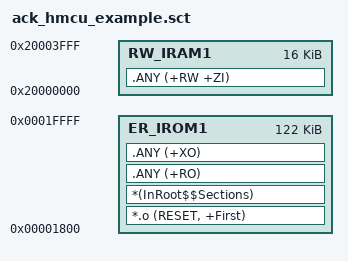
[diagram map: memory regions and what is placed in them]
LR_IROM1 0x00001800 0x0001e800  {    ; load region size_region
  ER_IROM1 0x00001800 0x0001e800  {  ; load address = execution address
   *.o (RESET, +First)
   *(InRoot$$Sections)
   .ANY (+RO)
   .ANY (+XO)
  }
  RW_IRAM1 0x20000000 0x00004000  {  ; RW data
   .ANY (+RW +ZI)
  }
}

